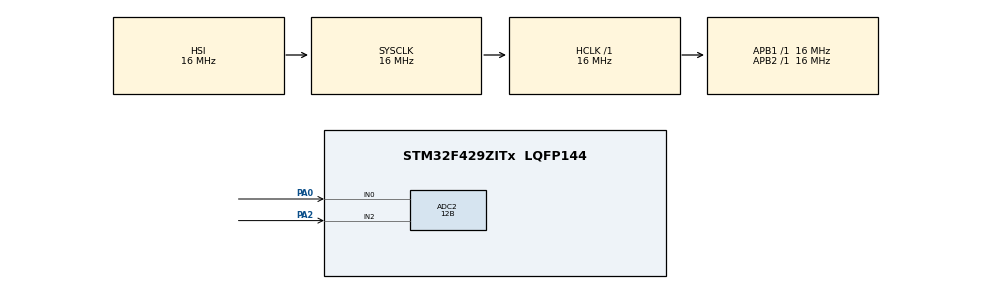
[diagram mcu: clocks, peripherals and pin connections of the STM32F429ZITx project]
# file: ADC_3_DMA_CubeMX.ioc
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ADC2.Channel-0\#ChannelRegularConversion=ADC_CHANNEL_0
ADC2.Channel-1\#ChannelRegularConversion=ADC_CHANNEL_2
ADC2.ClockPrescaler=ADC_CLOCK_SYNC_PCLK_DIV2
ADC2.ContinuousConvMode=ENABLE
ADC2.DMAContinuousRequests=ENABLE
ADC2.DataAlign=ADC_DATAALIGN_RIGHT
ADC2.DiscontinuousConvMode=DISABLE
ADC2.EOCSelection=ADC_EOC_SINGLE_CONV
ADC2.EnableAnalogWatchDog=false
ADC2.ExternalTrigConv=ADC_SOFTWARE_START
ADC2.ExternalTrigConvEdge=ADC_EXTERNALTRIGCONVEDGE_NONE
ADC2.InjNumberOfConversion=0
ADC2.NbrOfConversion=2
ADC2.NbrOfConversionFlag=1
ADC2.Rank-0\#ChannelRegularConversion=1
ADC2.Rank-1\#ChannelRegularConversion=2
ADC2.Resolution=ADC_RESOLUTION_12B
ADC2.SamplingTime-0\#ChannelRegularConversion=ADC_SAMPLETIME_480CYCLES
ADC2.SamplingTime-1\#ChannelRegularConversion=ADC_SAMPLETIME_3CYCLES
ADC2.ScanConvMode=ENABLE
Dma.ADC2.0.Direction=DMA_PERIPH_TO_MEMORY
Dma.ADC2.0.FIFOMode=DMA_FIFOMODE_DISABLE
Dma.ADC2.0.Instance=DMA2_Stream2
Dma.ADC2.0.MemDataAlignment=DMA_MDATAALIGN_HALFWORD
Dma.ADC2.0.MemInc=DMA_MINC_ENABLE
Dma.ADC2.0.Mode=DMA_CIRCULAR
Dma.ADC2.0.PeriphDataAlignment=DMA_PDATAALIGN_HALFWORD
Dma.ADC2.0.PeriphInc=DMA_PINC_DISABLE
Dma.ADC2.0.Priority=DMA_PRIORITY_LOW
Dma.Request0=ADC2
Mcu.Family=STM32F4
Mcu.Name=STM32F429ZITx
Mcu.Package=LQFP144
NVIC.DMA2_Stream2_IRQn=true\:0\:0\:false\:false\:true\:false
NVIC.PriorityGroup=NVIC_PRIORITYGROUP_4
PA0/WKUP.Signal=ADCx_IN0
PA2.Signal=ADCx_IN2
ProjectManager.HeapSize=0x200
ProjectManager.StackSize=0x400
ProjectManager.TargetToolchain=SW4STM32
RCC.AHBFreq_Value=16000000
RCC.APB1Freq_Value=16000000
RCC.APB2Freq_Value=16000000
RCC.CortexFreq_Value=16000000
RCC.HSE_VALUE=25000000
RCC.HSI_VALUE=16000000
RCC.LSE_VALUE=32768
RCC.SYSCLKFreq_VALUE=16000000
RCC.VCOOutputFreq_Value=192000000
SH.ADCx_IN0.0=ADC2_IN0,IN0
SH.ADCx_IN2.0=ADC2_IN2,IN2
board=custom

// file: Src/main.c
/**
  ******************************************************************************
  * @file           : main.c
  * @brief          : Main program body
  ******************************************************************************
  ** This notice applies to any and all portions of this file
  * that are not between comment pairs USER CODE BEGIN and
  * USER CODE END. Other portions of this file, whether
  * inserted by the user or by software development tools
  * are owned by their respective copyright owners.
  *
  * COPYRIGHT(c) 2018 STMicroelectronics
  *
  * Redistribution and use in source and binary forms, with or without modification,
  * are permitted provided that the following conditions are met:
  *   1. Redistributions of source code must retain the above copyright notice,
  *      this list of conditions and the following disclaimer.
  *   2. Redistributions in binary form must reproduce the above copyright notice,
  *      this list of conditions and the following disclaimer in the documentation
  *      and/or other materials provided with the distribution.
  *   3. Neither the name of STMicroelectronics nor the names of its contributors
  *      may be used to endorse or promote products derived from this software
  *      without specific prior written permission.
  *
  * THIS SOFTWARE IS PROVIDED BY THE COPYRIGHT HOLDERS AND CONTRIBUTORS "AS IS"
  * AND ANY EXPRESS OR IMPLIED WARRANTIES, INCLUDING, BUT NOT LIMITED TO, THE
  * IMPLIED WARRANTIES OF MERCHANTABILITY AND FITNESS FOR A PARTICULAR PURPOSE ARE
  * DISCLAIMED. IN NO EVENT SHALL THE COPYRIGHT HOLDER OR CONTRIBUTORS BE LIABLE
  * FOR ANY DIRECT, INDIRECT, INCIDENTAL, SPECIAL, EXEMPLARY, OR CONSEQUENTIAL
  * DAMAGES (INCLUDING, BUT NOT LIMITED TO, PROCUREMENT OF SUBSTITUTE GOODS OR
  * SERVICES; LOSS OF USE, DATA, OR PROFITS; OR BUSINESS INTERRUPTION) HOWEVER
  * CAUSED AND ON ANY THEORY OF LIABILITY, WHETHER IN CONTRACT, STRICT LIABILITY,
  * OR TORT (INCLUDING NEGLIGENCE OR OTHERWISE) ARISING IN ANY WAY OUT OF THE USE
  * OF THIS SOFTWARE, EVEN IF ADVISED OF THE POSSIBILITY OF SUCH DAMAGE.
  *
  ******************************************************************************
  */
#include "main.h"
#include "stm32f4xx_hal.h"

ADC_HandleTypeDef hadc2;
DMA_HandleTypeDef hdma_adc2;

uint16_t values[2];
/* USER CODE BEGIN PV */
/* Private variables ---------------------------------------------------------*/

/* USER CODE END PV */

void SystemClock_Config(void);
static void MX_GPIO_Init(void);
static void MX_DMA_Init(void);
static void MX_ADC2_Init(void);

/* USER CODE BEGIN PFP */
/* Private function prototypes -----------------------------------------------*/

/* USER CODE END PFP */

int main(void)
{

  /* MCU Configuration----------------------------------------------------------*/

  /* Reset of all peripherals, Initializes the Flash interface and the Systick. */
  HAL_Init();

  /* Configure the system clock */
  SystemClock_Config();

  /* Initialize all configured peripherals */
  MX_GPIO_Init();
  MX_DMA_Init();
  MX_ADC2_Init();
  /* USER CODE BEGIN 2 */

  HAL_ADC_Start_DMA(&hadc2, values, 2);		//

  /* USER CODE END 2 */

  /* Infinite loop */
  while (1)
  {

  }

}

void SystemClock_Config(void)
{

  RCC_OscInitTypeDef RCC_OscInitStruct;
  RCC_ClkInitTypeDef RCC_ClkInitStruct;

    /**Configure the main internal regulator output voltage
    */
  __HAL_RCC_PWR_CLK_ENABLE();

  __HAL_PWR_VOLTAGESCALING_CONFIG(PWR_REGULATOR_VOLTAGE_SCALE3);

    /**Initializes the CPU, AHB and APB busses clocks
    */
  RCC_OscInitStruct.OscillatorType = RCC_OSCILLATORTYPE_HSI;
  RCC_OscInitStruct.HSIState = RCC_HSI_ON;
  RCC_OscInitStruct.HSICalibrationValue = 16;
  RCC_OscInitStruct.PLL.PLLState = RCC_PLL_NONE;
  if (HAL_RCC_OscConfig(&RCC_OscInitStruct) != HAL_OK)
  {
    _Error_Handler(__FILE__, __LINE__);
  }

    /**Initializes the CPU, AHB and APB busses clocks
    */
  RCC_ClkInitStruct.ClockType = RCC_CLOCKTYPE_HCLK|RCC_CLOCKTYPE_SYSCLK
                              |RCC_CLOCKTYPE_PCLK1|RCC_CLOCKTYPE_PCLK2;
  RCC_ClkInitStruct.SYSCLKSource = RCC_SYSCLKSOURCE_HSI;
  RCC_ClkInitStruct.AHBCLKDivider = RCC_SYSCLK_DIV1;
  RCC_ClkInitStruct.APB1CLKDivider = RCC_HCLK_DIV1;
  RCC_ClkInitStruct.APB2CLKDivider = RCC_HCLK_DIV1;

  if (HAL_RCC_ClockConfig(&RCC_ClkInitStruct, FLASH_LATENCY_0) != HAL_OK)
  {
    _Error_Handler(__FILE__, __LINE__);
  }

    /**Configure the Systick interrupt time
    */
  HAL_SYSTICK_Config(HAL_RCC_GetHCLKFreq()/1000);

    /**Configure the Systick
    */
  HAL_SYSTICK_CLKSourceConfig(SYSTICK_CLKSOURCE_HCLK);

  /* SysTick_IRQn interrupt configuration */
  HAL_NVIC_SetPriority(SysTick_IRQn, 0, 0);
}

/* ADC2 init function */
static void MX_ADC2_Init(void)
{

  ADC_ChannelConfTypeDef sConfig;

    /**Configure the global features of the ADC (Clock, Resolution, Data Alignment and number of conversion)
    */
  hadc2.Instance = ADC2;
  hadc2.Init.ClockPrescaler = ADC_CLOCK_SYNC_PCLK_DIV2;
  hadc2.Init.Resolution = ADC_RESOLUTION_12B;
  hadc2.Init.ScanConvMode = ENABLE;
  hadc2.Init.ContinuousConvMode = ENABLE;
  hadc2.Init.DiscontinuousConvMode = DISABLE;
  hadc2.Init.ExternalTrigConvEdge = ADC_EXTERNALTRIGCONVEDGE_NONE;
  hadc2.Init.ExternalTrigConv = ADC_SOFTWARE_START;
  hadc2.Init.DataAlign = ADC_DATAALIGN_RIGHT;
  hadc2.Init.NbrOfConversion = 2;
  hadc2.Init.DMAContinuousRequests = ENABLE;
  hadc2.Init.EOCSelection = ADC_EOC_SINGLE_CONV;
  if (HAL_ADC_Init(&hadc2) != HAL_OK)
  {
    _Error_Handler(__FILE__, __LINE__);
  }

    /**Configure for the selected ADC regular channel its corresponding rank in the sequencer and its sample time.
    */
  sConfig.Channel = ADC_CHANNEL_0;
  sConfig.Rank = 1;
  sConfig.SamplingTime = ADC_SAMPLETIME_480CYCLES;
  if (HAL_ADC_ConfigChannel(&hadc2, &sConfig) != HAL_OK)
  {
    _Error_Handler(__FILE__, __LINE__);
  }

    /**Configure for the selected ADC regular channel its corresponding rank in the sequencer and its sample time.
    */
  sConfig.Channel = ADC_CHANNEL_2;
  sConfig.Rank = 2;
  sConfig.SamplingTime = ADC_SAMPLETIME_3CYCLES;
  if (HAL_ADC_ConfigChannel(&hadc2, &sConfig) != HAL_OK)
  {
    _Error_Handler(__FILE__, __LINE__);
  }

}

static void MX_DMA_Init(void)
{
  /* DMA controller clock enable */
  __HAL_RCC_DMA2_CLK_ENABLE();

  /* DMA interrupt init */
  /* DMA2_Stream2_IRQn interrupt configuration */
  HAL_NVIC_SetPriority(DMA2_Stream2_IRQn, 0, 0);
  HAL_NVIC_EnableIRQ(DMA2_Stream2_IRQn);

}

/** Pinout Configuration
*/
static void MX_GPIO_Init(void)
{

  /* GPIO Ports Clock Enable */
  __HAL_RCC_GPIOA_CLK_ENABLE();

}

void _Error_Handler(char *file, int line)
{
  while(1)
  {
  }
}

/************************ (C) COPYRIGHT STMicroelectronics *****END OF FILE****/
